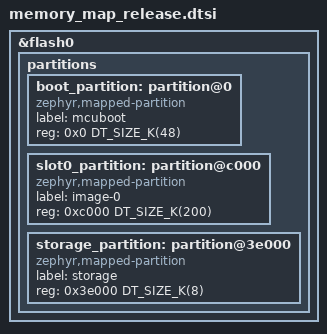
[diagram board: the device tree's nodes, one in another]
/*
 * Copyright (c) 2026 Nordic Semiconductor ASA
 *
 * SPDX-License-Identifier: LicenseRef-Nordic-5-Clause
 */

&flash0 {
	/delete-node/ partitions;

	partitions {
		#address-cells = <1>;
		#size-cells = <1>;
		ranges;

		boot_partition: partition@0 {
			compatible = "zephyr,mapped-partition";
			label = "mcuboot";
			reg = <0x0 DT_SIZE_K(48)>;
		};

		slot0_partition: partition@c000 {
			compatible = "zephyr,mapped-partition";
			label = "image-0";
			reg = <0xc000 DT_SIZE_K(200)>;
		};

		storage_partition: partition@3e000 {
			compatible = "zephyr,mapped-partition";
			label = "storage";
			reg = <0x3e000 DT_SIZE_K(8)>;
		};
	};
};
